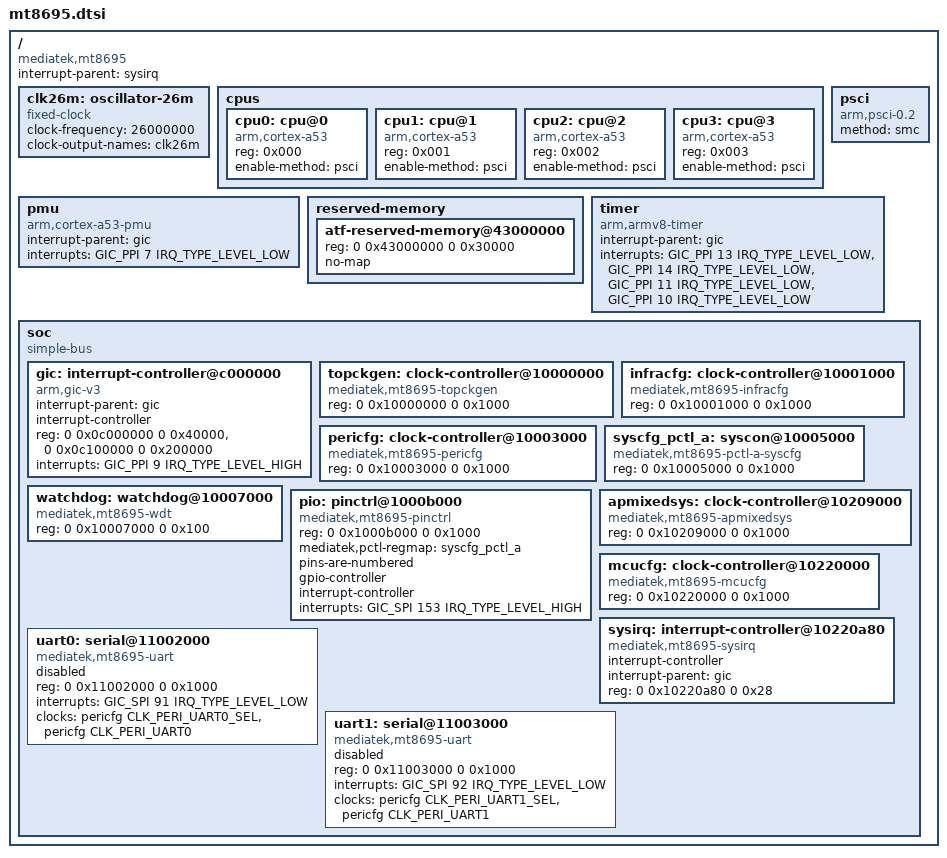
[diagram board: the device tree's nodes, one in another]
// SPDX-License-Identifier: (GPL-2.0 OR MIT)
/*
 * MediaTek MT8695 SoC
 *
 * Bring-up subset: CPUs, interrupt controllers, timers, the core clock
 * controllers, pinctrl and the UARTs.
 */

#include <dt-bindings/clock/mediatek,mt8695-clk.h>
#include <dt-bindings/interrupt-controller/arm-gic.h>
#include <dt-bindings/interrupt-controller/irq.h>

/ {
	compatible = "mediatek,mt8695";
	interrupt-parent = <&sysirq>;
	#address-cells = <2>;
	#size-cells = <2>;

	clk26m: oscillator-26m {
		compatible = "fixed-clock";
		#clock-cells = <0>;
		clock-frequency = <26000000>;
		clock-output-names = "clk26m";
	};

	cpus {
		#address-cells = <1>;
		#size-cells = <0>;

		cpu0: cpu@0 {
			device_type = "cpu";
			compatible = "arm,cortex-a53";
			reg = <0x000>;
			enable-method = "psci";
		};

		cpu1: cpu@1 {
			device_type = "cpu";
			compatible = "arm,cortex-a53";
			reg = <0x001>;
			enable-method = "psci";
		};

		cpu2: cpu@2 {
			device_type = "cpu";
			compatible = "arm,cortex-a53";
			reg = <0x002>;
			enable-method = "psci";
		};

		cpu3: cpu@3 {
			device_type = "cpu";
			compatible = "arm,cortex-a53";
			reg = <0x003>;
			enable-method = "psci";
		};
	};

	pmu {
		compatible = "arm,cortex-a53-pmu";
		interrupt-parent = <&gic>;
		interrupts = <GIC_PPI 7 IRQ_TYPE_LEVEL_LOW>;
	};

	psci {
		compatible = "arm,psci-0.2";
		method = "smc";
	};

	reserved-memory {
		#address-cells = <2>;
		#size-cells = <2>;
		ranges;

		/* BL31 (ARM Trusted Firmware) */
		atf-reserved-memory@43000000 {
			reg = <0 0x43000000 0 0x30000>;
			no-map;
		};
	};

	timer {
		compatible = "arm,armv8-timer";
		interrupt-parent = <&gic>;
		interrupts = <GIC_PPI 13 IRQ_TYPE_LEVEL_LOW>,
			     <GIC_PPI 14 IRQ_TYPE_LEVEL_LOW>,
			     <GIC_PPI 11 IRQ_TYPE_LEVEL_LOW>,
			     <GIC_PPI 10 IRQ_TYPE_LEVEL_LOW>;
	};

	soc {
		compatible = "simple-bus";
		#address-cells = <2>;
		#size-cells = <2>;
		ranges;

		gic: interrupt-controller@c000000 {
			compatible = "arm,gic-v3";
			#interrupt-cells = <3>;
			interrupt-parent = <&gic>;
			interrupt-controller;
			reg = <0 0x0c000000 0 0x40000>,		/* GICD */
			      <0 0x0c100000 0 0x200000>;	/* GICR */
			interrupts = <GIC_PPI 9 IRQ_TYPE_LEVEL_HIGH>;
		};

		topckgen: clock-controller@10000000 {
			compatible = "mediatek,mt8695-topckgen", "syscon";
			reg = <0 0x10000000 0 0x1000>;
			#clock-cells = <1>;
		};

		infracfg: clock-controller@10001000 {
			compatible = "mediatek,mt8695-infracfg", "syscon";
			reg = <0 0x10001000 0 0x1000>;
			#clock-cells = <1>;
		};

		pericfg: clock-controller@10003000 {
			compatible = "mediatek,mt8695-pericfg", "syscon";
			reg = <0 0x10003000 0 0x1000>;
			#clock-cells = <1>;
		};

		syscfg_pctl_a: syscon@10005000 {
			compatible = "mediatek,mt8695-pctl-a-syscfg", "syscon";
			reg = <0 0x10005000 0 0x1000>;
		};

		watchdog: watchdog@10007000 {
			compatible = "mediatek,mt8695-wdt",
				     "mediatek,mt6589-wdt";
			reg = <0 0x10007000 0 0x100>;
		};

		pio: pinctrl@1000b000 {
			compatible = "mediatek,mt8695-pinctrl";
			reg = <0 0x1000b000 0 0x1000>;
			mediatek,pctl-regmap = <&syscfg_pctl_a>;
			pins-are-numbered;
			gpio-controller;
			#gpio-cells = <2>;
			interrupt-controller;
			#interrupt-cells = <2>;
			interrupts = <GIC_SPI 153 IRQ_TYPE_LEVEL_HIGH>;
		};

		apmixedsys: clock-controller@10209000 {
			compatible = "mediatek,mt8695-apmixedsys", "syscon";
			reg = <0 0x10209000 0 0x1000>;
			#clock-cells = <1>;
		};

		mcucfg: clock-controller@10220000 {
			compatible = "mediatek,mt8695-mcucfg", "syscon";
			reg = <0 0x10220000 0 0x1000>;
			#clock-cells = <1>;
		};

		sysirq: interrupt-controller@10220a80 {
			compatible = "mediatek,mt8695-sysirq",
				     "mediatek,mt6577-sysirq";
			interrupt-controller;
			#interrupt-cells = <3>;
			interrupt-parent = <&gic>;
			reg = <0 0x10220a80 0 0x28>;
		};

		uart0: serial@11002000 {
			compatible = "mediatek,mt8695-uart",
				     "mediatek,mt6577-uart";
			reg = <0 0x11002000 0 0x1000>;
			interrupts = <GIC_SPI 91 IRQ_TYPE_LEVEL_LOW>;
			clocks = <&pericfg CLK_PERI_UART0_SEL>, <&pericfg CLK_PERI_UART0>;
			clock-names = "baud", "bus";
			status = "disabled";
		};

		uart1: serial@11003000 {
			compatible = "mediatek,mt8695-uart",
				     "mediatek,mt6577-uart";
			reg = <0 0x11003000 0 0x1000>;
			interrupts = <GIC_SPI 92 IRQ_TYPE_LEVEL_LOW>;
			clocks = <&pericfg CLK_PERI_UART1_SEL>, <&pericfg CLK_PERI_UART1>;
			clock-names = "baud", "bus";
			status = "disabled";
		};
	};
};
